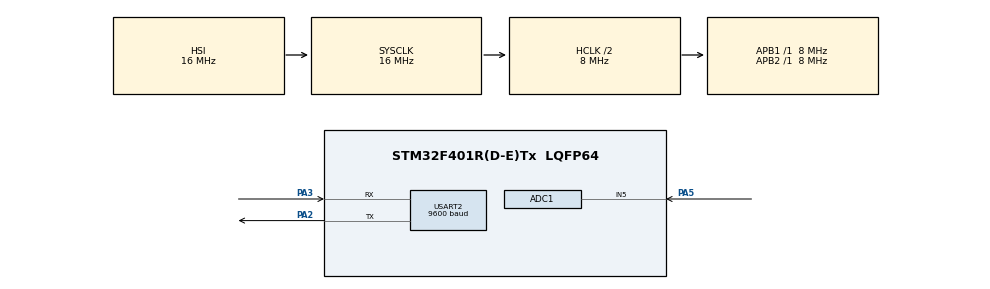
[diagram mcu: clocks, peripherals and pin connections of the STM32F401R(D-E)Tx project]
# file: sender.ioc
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ADC1.Channel-0\#ChannelRegularConversion=ADC_CHANNEL_5
ADC1.ContinuousConvMode=ENABLE
ADC1.NbrOfConversion=1
ADC1.NbrOfConversionFlag=1
ADC1.Rank-0\#ChannelRegularConversion=1
ADC1.SamplingTime-0\#ChannelRegularConversion=ADC_SAMPLETIME_28CYCLES
ADC1.ScanConvMode=ENABLE
ADC1.master=1
Mcu.Family=STM32F4
Mcu.Name=STM32F401R(D-E)Tx
Mcu.Package=LQFP64
NVIC.ADC_IRQn=true\:0\:0\:false\:false\:true\:true\:true
NVIC.PriorityGroup=NVIC_PRIORITYGROUP_4
NVIC.USART2_IRQn=true\:0\:0\:false\:false\:true\:true\:true
PA2.Mode=Asynchronous
PA2.Signal=USART2_TX
PA3.Mode=Asynchronous
PA3.Signal=USART2_RX
PA5.Signal=ADCx_IN5
ProjectManager.HeapSize=0x200
ProjectManager.StackSize=0x400
ProjectManager.TargetToolchain=MDK-ARM V5.27
RCC.AHBCLKDivider=RCC_SYSCLK_DIV2
RCC.AHBFreq_Value=8000000
RCC.APB1Freq_Value=8000000
RCC.APB1TimFreq_Value=8000000
RCC.APB2Freq_Value=8000000
RCC.APB2TimFreq_Value=8000000
RCC.CortexFreq_Value=8000000
RCC.HCLKFreq_Value=8000000
RCC.HSE_VALUE=25000000
RCC.HSI_VALUE=16000000
RCC.LSE_VALUE=32768
RCC.SYSCLKFreq_VALUE=16000000
RCC.VCOOutputFreq_Value=192000000
SH.ADCx_IN5.0=ADC1_IN5,IN5
USART2.BaudRate=9600
USART2.Mode=MODE_TX_RX
USART2.VirtualMode=VM_ASYNC
board=custom

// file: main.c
/* USER CODE BEGIN Header */
/**
  ******************************************************************************
  * @file           : main.c
  * @brief          : Main program body
  ******************************************************************************
  * @attention
  *
  * <h2><center>&copy; Copyright (c) 2021 STMicroelectronics.
  * All rights reserved.</center></h2>
  *
  * This software component is licensed by ST under BSD 3-Clause license,
  * the "License"; You may not use this file except in compliance with the
  * License. You may obtain a copy of the License at:
  *                        opensource.org/licenses/BSD-3-Clause
  *
  ******************************************************************************
  */
/* USER CODE END Header */
#include "main.h"
#include "stdio.h"

ADC_HandleTypeDef hadc1;

UART_HandleTypeDef huart2;

/* USER CODE BEGIN PV */
float adcValue_f;
int adcValue_i;
/* USER CODE END PV */

void SystemClock_Config(void);
static void MX_GPIO_Init(void);
static void MX_USART2_UART_Init(void);
static void MX_ADC1_Init(void);
/* USER CODE BEGIN PFP */
#ifdef __GNUC__
/* With GCC/RAISONANCE, small printf (option LD Linker->Libraries->Small printf
   set to 'Yes') calls __io_putchar() */
#define PUTCHAR_PROTOTYPE int __io_putchar(int ch)
#define GETCHAR_PROTOTYPE int __io_getchar(void)
#else
#define PUTCHAR_PROTOTYPE int fputc(int ch, FILE *f)
#define GETCHAR_PROTOTYPE int fgetc(FILE *f)
#endif /* __GNUC__ */

PUTCHAR_PROTOTYPE
    {
    HAL_UART_Transmit(&huart2,(uint8_t*)&ch,1,100);

        return ch;

    }

/* USER CODE END PFP */

/* USER CODE BEGIN 0 */
void UART_init(){
	RCC->AHB1ENR |= RCC_AHB1ENR_GPIOAEN; /* enable GPIOA clock */
	RCC->APB1ENR |= RCC_APB1ENR_USART2EN; 							/* enable USART2 clock */

		/* Configure PA2,PA3 for USART2_TX */
	GPIOA->OSPEEDR |= 0x80; //10 00 00 00
	GPIOA->OSPEEDR |= 0x20; //00 10 00 00

	GPIOA->AFR[0] &= ~0x0FF00;
	GPIOA->AFR[0] |= 0x07700; /* alt7 for USART2 */
	GPIOA->MODER  &= ~0x00F0;
	GPIOA->MODER  |= 0x00A0; // enable alternate function for PA3,PA2   10 10 00 00
	USART2->BRR = 0x0683; 	 /* 9600 baud @ 16 MHz */
	USART2->CR1 |= 0x0008; /* enable Tx, 8-bit data */
	USART2->CR1 |= 0x0004; /* enable Rx, 8-bit data */
	USART2->CR2 |= (2 << 12); 	 /* 1 stop bit*/
	USART2->CR3 = 0x0000; 	 /* no flow control */
	USART2->CR1 |= 0x2000;   /* enable USART2 */

}
void UART_Transmit(int digit){
	int big = digit / 10;
	int small = digit % 10;
	USART2->DR = big + '0';
	while(!READ_BIT(USART2->SR, USART_SR_TC)){}
  USART2->DR = small + '0';
	while(!READ_BIT(USART2->SR, USART_SR_TC)){}
}

/* USER CODE END 0 */

int main(void)
{

  /* MCU Configuration--------------------------------------------------------*/

  /* Reset of all peripherals, Initializes the Flash interface and the Systick. */
  HAL_Init();

  /* Configure the system clock */
  SystemClock_Config();

  /* Initialize all configured peripherals */
  MX_GPIO_Init();
  MX_USART2_UART_Init();
	USART2->BRR = 0x0683; 	 /* 9600 baud @ 16 MHz */
  MX_ADC1_Init();

  /* Infinite loop */
  /* USER CODE BEGIN WHILE */
	//HAL_UART_Transmit(&huart2, (uint8_t*)"7", strlen("7"), 100);
	//HAL_Delay(100);

	while (1)
  {
		HAL_ADC_Init(&hadc1);
		HAL_ADC_Start(&hadc1);
		if (HAL_ADC_PollForConversion(&hadc1, 10) == HAL_OK)
    {
			adcValue_f = HAL_ADC_GetValue(&hadc1);
			adcValue_f = (adcValue_f * 5) / 4095;
			adcValue_f = adcValue_f * 10;

		}
		adcValue_i = (int) adcValue_f;

		UART_Transmit(adcValue_i);
    /* USER CODE END WHILE */

		//HAL_UART_Transmit(&huart2, (uint8_t *)"2", 1, 100);

  }
}

void SystemClock_Config(void)
{
  RCC_OscInitTypeDef RCC_OscInitStruct = {0};
  RCC_ClkInitTypeDef RCC_ClkInitStruct = {0};

  /** Configure the main internal regulator output voltage
  */
  __HAL_RCC_PWR_CLK_ENABLE();
  __HAL_PWR_VOLTAGESCALING_CONFIG(PWR_REGULATOR_VOLTAGE_SCALE2);
  /** Initializes the RCC Oscillators according to the specified parameters
  * in the RCC_OscInitTypeDef structure.
  */
  RCC_OscInitStruct.OscillatorType = RCC_OSCILLATORTYPE_HSI;
  RCC_OscInitStruct.HSIState = RCC_HSI_ON;
  RCC_OscInitStruct.HSICalibrationValue = RCC_HSICALIBRATION_DEFAULT;
  RCC_OscInitStruct.PLL.PLLState = RCC_PLL_NONE;
  if (HAL_RCC_OscConfig(&RCC_OscInitStruct) != HAL_OK)
  {
    Error_Handler();
  }
  /** Initializes the CPU, AHB and APB buses clocks
  */
  RCC_ClkInitStruct.ClockType = RCC_CLOCKTYPE_HCLK|RCC_CLOCKTYPE_SYSCLK
                              |RCC_CLOCKTYPE_PCLK1|RCC_CLOCKTYPE_PCLK2;
  RCC_ClkInitStruct.SYSCLKSource = RCC_SYSCLKSOURCE_HSI;
  RCC_ClkInitStruct.AHBCLKDivider = RCC_SYSCLK_DIV2;
  RCC_ClkInitStruct.APB1CLKDivider = RCC_HCLK_DIV1;
  RCC_ClkInitStruct.APB2CLKDivider = RCC_HCLK_DIV1;

  if (HAL_RCC_ClockConfig(&RCC_ClkInitStruct, FLASH_LATENCY_0) != HAL_OK)
  {
    Error_Handler();
  }
}

static void MX_ADC1_Init(void)
{

  ADC_ChannelConfTypeDef sConfig = {0};

  /** Configure the global features of the ADC (Clock, Resolution, Data Alignment and number of conversion)
  */
  hadc1.Instance = ADC1;
  hadc1.Init.ClockPrescaler = ADC_CLOCK_SYNC_PCLK_DIV2;
  hadc1.Init.Resolution = ADC_RESOLUTION_12B;
  hadc1.Init.ScanConvMode = ENABLE;
  hadc1.Init.ContinuousConvMode = ENABLE;
  hadc1.Init.DiscontinuousConvMode = DISABLE;
  hadc1.Init.ExternalTrigConvEdge = ADC_EXTERNALTRIGCONVEDGE_NONE;
  hadc1.Init.ExternalTrigConv = ADC_SOFTWARE_START;
  hadc1.Init.DataAlign = ADC_DATAALIGN_RIGHT;
  hadc1.Init.NbrOfConversion = 1;
  hadc1.Init.DMAContinuousRequests = DISABLE;
  hadc1.Init.EOCSelection = ADC_EOC_SINGLE_CONV;
  if (HAL_ADC_Init(&hadc1) != HAL_OK)
  {
    Error_Handler();
  }
  /** Configure for the selected ADC regular channel its corresponding rank in the sequencer and its sample time.
  */
  sConfig.Channel = ADC_CHANNEL_5;
  sConfig.Rank = 1;
  sConfig.SamplingTime = ADC_SAMPLETIME_84CYCLES;
  if (HAL_ADC_ConfigChannel(&hadc1, &sConfig) != HAL_OK)
  {
    Error_Handler();
  }

}

static void MX_USART2_UART_Init(void)
{

  huart2.Instance = USART2;
  //huart2.Init.BaudRate = 9600;
  huart2.Init.WordLength = UART_WORDLENGTH_8B;
  huart2.Init.StopBits = UART_STOPBITS_1;
  huart2.Init.Parity = UART_PARITY_NONE;
  huart2.Init.Mode = UART_MODE_TX_RX;
  huart2.Init.HwFlowCtl = UART_HWCONTROL_NONE;
  huart2.Init.OverSampling = UART_OVERSAMPLING_16;

  //UART_init();
  if (HAL_UART_Init(&huart2) != HAL_OK)
  {
    Error_Handler();
  }

}

static void MX_GPIO_Init(void)
{

  /* GPIO Ports Clock Enable */
  __HAL_RCC_GPIOA_CLK_ENABLE();

}

void Error_Handler(void)
{
  __disable_irq();
  while (1)
  {
  }
}

/************************ (C) COPYRIGHT STMicroelectronics *****END OF FILE****/
